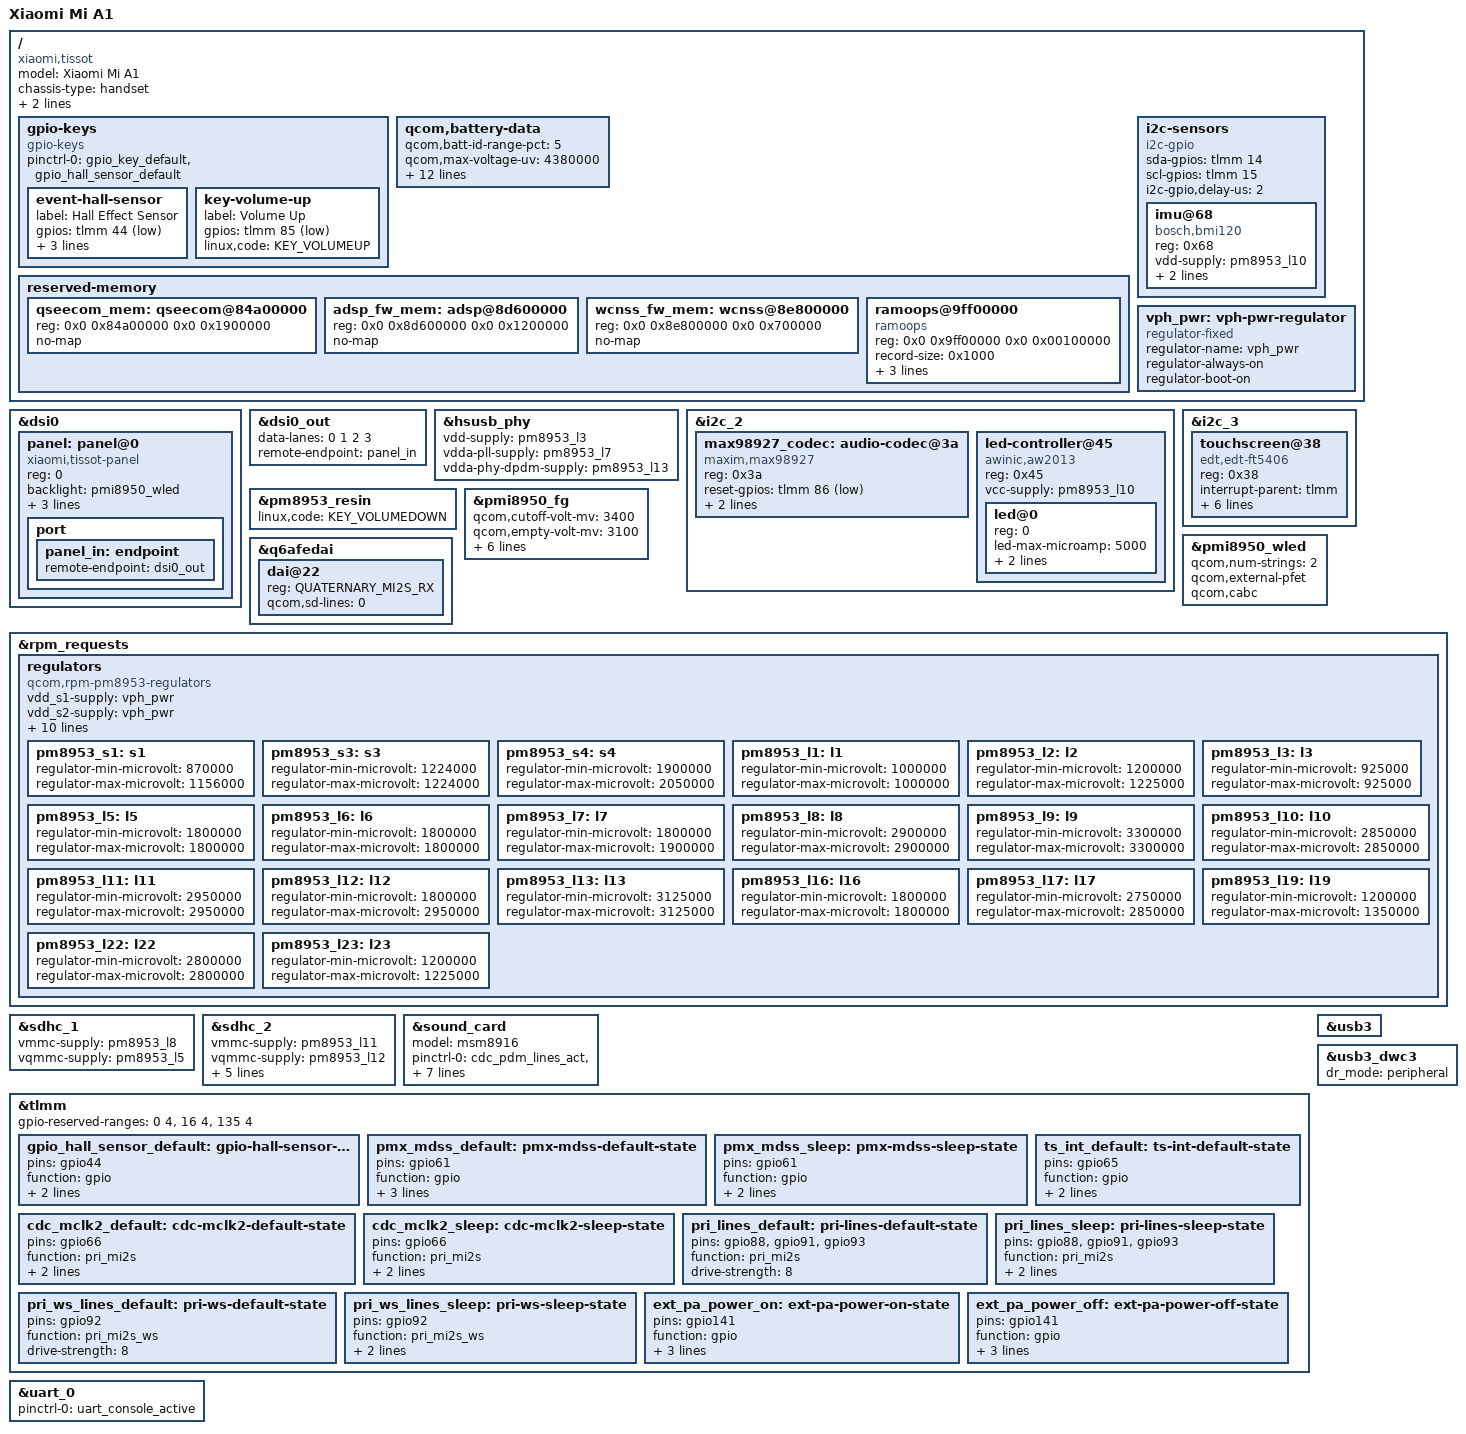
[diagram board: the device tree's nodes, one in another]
// SPDX-License-Identifier: BSD-3-Clause
/*
 * Copyright (c) 2022, Danila Tikhonov <JIaxyga@protonmail.com>
 * Copyright (c) 2022, Anton Bambura <jenneron@protonmail.com>
 */
/dts-v1/;

#include "msm8953.dtsi"
#include "pm8953.dtsi"
#include "pmi8950.dtsi"

#include <dt-bindings/gpio/gpio.h>
#include <dt-bindings/leds/common.h>

/delete-node/ &adsp_fw_mem;
/delete-node/ &qseecom_mem;
/delete-node/ &wcnss_fw_mem;

/ {
	model = "Xiaomi Mi A1";
	compatible = "xiaomi,tissot", "qcom,msm8953";
	chassis-type = "handset";
	qcom,msm-id = <293 0>;
	qcom,board-id = <0x1000b 0x00>;

	gpio-keys {
		compatible = "gpio-keys";

		pinctrl-names = "default";
		pinctrl-0 = <&gpio_key_default>, <&gpio_hall_sensor_default>;

		event-hall-sensor {
			label = "Hall Effect Sensor";
			gpios = <&tlmm 44 GPIO_ACTIVE_LOW>;
			linux,input-type = <EV_SW>;
			linux,code = <SW_LID>;
			linux,can-disable;
		};

		key-volume-up {
			label = "Volume Up";
			gpios = <&tlmm 85 GPIO_ACTIVE_LOW>;
			linux,code = <KEY_VOLUMEUP>;
		};
	};

	qcom,battery-data {
		qcom,batt-id-range-pct = <5>;
		qcom,max-voltage-uv = <4380000>;
		qcom,nom-batt-capacity-mah = <3080>;
		qcom,batt-id-kohm = <50>;
		qcom,battery-beta = <3380>;
		qcom,battery-type = "battey_qrd_coslight_3080mah";
		qcom,chg-rslow-comp-c1 = <3969816>;
		qcom,chg-rslow-comp-c2 = <7140145>;
		qcom,chg-rs-to-rslow = <997019>;
		qcom,chg-rslow-comp-thr = <0xB8>;
		qcom,checksum = <0x5DAD>;
		qcom,thermal-coefficients = [c8 86 c1 50 d3 37];
		qcom,fg-profile-data = [E2 83 DF 7C
					10 81 12 77
					65 83 51 74
					74 89 94 94
					33 82 B0 99
					A5 BC 1D C9
					55 10 02 88
					9A 7D 74 81
					8D 77 4E 83
					CD 70 15 61
					CD 7E 4F 82
					9D 99 DF BC
					B5 C9 59 0C
					24 0C 15 59
					14 70 B2 FD
					A4 3F 23 3D
					6E 33 00 00
					35 46 01 38
					FE 12 00 00
					00 00 00 00
					00 00 00 00
					97 6B B4 6A
					EF 60 0B 81
					92 6E 72 60
					3E 59 C0 79
					5B 6D 56 5B
					18 7F 64 9A
					18 E9 61 55
					5F A0 71 0C
					28 00 FF 36
					F0 11 30 03
					00 00 00 0C];
	};

	reserved-memory {
		qseecom_mem: qseecom@84a00000 {
			reg = <0x0 0x84a00000 0x0 0x1900000>;
			no-map;
		};

		adsp_fw_mem: adsp@8d600000 {
			reg = <0x0 0x8d600000 0x0 0x1200000>;
			no-map;
		};

		wcnss_fw_mem: wcnss@8e800000 {
			reg = <0x0 0x8e800000 0x0 0x700000>;
			no-map;
		};

		ramoops@9ff00000 {
			compatible = "ramoops";
			reg = <0x0 0x9ff00000 0x0 0x00100000>;
			record-size = <0x1000>;
			console-size = <0x80000>;
			ftrace-size = <0x1000>;
			pmsg-size = <0x8000>;
		};
	};

	/*
	 * We bitbang on &i2c_4 because BLSP is protected by TZ as sensors are
	 * normally proxied via ADSP firmware. GPIOs aren't protected.
	 */
	i2c-sensors {
		compatible = "i2c-gpio";
		sda-gpios = <&tlmm 14 (GPIO_ACTIVE_HIGH|GPIO_OPEN_DRAIN)>;
		scl-gpios = <&tlmm 15 (GPIO_ACTIVE_HIGH|GPIO_OPEN_DRAIN)>;
		i2c-gpio,delay-us = <2>; /* ~100 kHz */
		#address-cells = <1>;
		#size-cells = <0>;

		imu@68 {
			compatible = "bosch,bmi120";
			reg = <0x68>;

			vdd-supply = <&pm8953_l10>;
			vddio-supply = <&pm8953_l6>;
			mount-matrix = "0", "1", "0",
					"1", "0", "0",
					"0", "0", "1";
		};
	};

	vph_pwr: vph-pwr-regulator {
		compatible = "regulator-fixed";
		regulator-name = "vph_pwr";
		regulator-always-on;
		regulator-boot-on;
	};
};

&dsi0 {
	panel: panel@0 {
		compatible = "xiaomi,tissot-panel";
		reg = <0>;

		backlight = <&pmi8950_wled>;

		reset-gpios = <&tlmm 61 GPIO_ACTIVE_LOW>;

		pinctrl-names = "default", "sleep";
		pinctrl-0 = <&pmx_mdss_default &mdss_te_default>;
		pinctrl-1 = <&pmx_mdss_sleep &mdss_te_default>;

		port {
			panel_in: endpoint {
				remote-endpoint = <&dsi0_out>;
			};
		};
	};
};

&dsi0_out {
	data-lanes = <0 1 2 3>;
	remote-endpoint = <&panel_in>;
};

&hsusb_phy {
	vdd-supply = <&pm8953_l3>;
	vdda-pll-supply = <&pm8953_l7>;
	vdda-phy-dpdm-supply = <&pm8953_l13>;

	status = "okay";
};

&i2c_2 {
	status = "okay";

	max98927_codec: audio-codec@3a {
		compatible = "maxim,max98927";
		reg = <0x3a>;

		reset-gpios = <&tlmm 86 GPIO_ACTIVE_LOW>;

		vmon-slot-no = <1>;
		imon-slot-no = <1>;

		#sound-dai-cells = <1>;
	};

	led-controller@45 {
		compatible = "awinic,aw2013";
		reg = <0x45>;

		vcc-supply = <&pm8953_l10>;

		#address-cells = <1>;
		#size-cells = <0>;

		led@0 {
			reg = <0>;
			led-max-microamp = <5000>;
			function = LED_FUNCTION_INDICATOR;
			color = <LED_COLOR_ID_WHITE>;
		};
	};
};

&i2c_3 {
	status = "okay";

	touchscreen@38 {
		compatible = "edt,edt-ft5406";
		reg = <0x38>;

		interrupt-parent = <&tlmm>;
		interrupts = <65 IRQ_TYPE_EDGE_FALLING>;

		pinctrl-names = "default";
		pinctrl-0 = <&ts_int_default>;

		reset-gpios = <&tlmm 64 GPIO_ACTIVE_LOW>;

		vcc-supply = <&pm8953_l10>;

		touchscreen-size-x = <1080>;
		touchscreen-size-y = <1920>;
	};
};

&pm8953_resin {
	linux,code = <KEY_VOLUMEDOWN>;
	status = "okay";
};

&pmi8950_fg {
	qcom,cutoff-volt-mv = <3400>;
	qcom,empty-volt-mv = <3100>;
	qcom,term-current-ma = <300>;
	qcom,chg-term-current-ma = <200>;
	qcom,fg-cc-cv-thr-mv = <4370>;
	qcom,fg-vbat-estimate-diff-mv = <250>;
	qcom,bcl-lm-thr-ma = <127>;
	qcom,bcl-mh-thr-ma = <405>;
};

&pmi8950_wled {
	qcom,num-strings = <2>;
	qcom,external-pfet;
	qcom,cabc;

	status = "okay";
};

&q6afedai {
	dai@22 {
		reg = <QUATERNARY_MI2S_RX>;
		qcom,sd-lines = <0>;
	};
};

&rpm_requests {
	regulators {
		compatible = "qcom,rpm-pm8953-regulators";

		vdd_s1-supply = <&vph_pwr>;
		vdd_s2-supply = <&vph_pwr>;
		vdd_s3-supply = <&vph_pwr>;
		vdd_s4-supply = <&vph_pwr>;
		vdd_s5-supply = <&vph_pwr>;
		vdd_s6-supply = <&vph_pwr>;
		vdd_s7-supply = <&vph_pwr>;
		vdd_l1-supply = <&pm8953_s3>;
		vdd_l2_l3-supply = <&pm8953_s3>;
		vdd_l4_l5_l6_l7_l16_l19-supply = <&pm8953_s4>;
		vdd_l8_l11_l12_l13_l14_l15-supply = <&vph_pwr>;
		vdd_l9_l10_l17_l18_l22-supply = <&vph_pwr>;

		pm8953_s1: s1 {
			regulator-min-microvolt = <870000>;
			regulator-max-microvolt = <1156000>;
		};

		pm8953_s3: s3 {
			regulator-min-microvolt = <1224000>;
			regulator-max-microvolt = <1224000>;
		};

		pm8953_s4: s4 {
			regulator-min-microvolt = <1900000>;
			regulator-max-microvolt = <2050000>;
		};

		pm8953_l1: l1 {
			regulator-min-microvolt = <1000000>;
			regulator-max-microvolt = <1000000>;
		};

		pm8953_l2: l2 {
			regulator-min-microvolt = <1200000>;
			regulator-max-microvolt = <1225000>;
		};

		pm8953_l3: l3 {
			regulator-min-microvolt = <925000>;
			regulator-max-microvolt = <925000>;
		};

		pm8953_l5: l5 {
			regulator-min-microvolt = <1800000>;
			regulator-max-microvolt = <1800000>;
		};

		pm8953_l6: l6 {
			regulator-min-microvolt = <1800000>;
			regulator-max-microvolt = <1800000>;
		};

		pm8953_l7: l7 {
			regulator-min-microvolt = <1800000>;
			regulator-max-microvolt = <1900000>;
		};

		pm8953_l8: l8 {
			regulator-min-microvolt = <2900000>;
			regulator-max-microvolt = <2900000>;
		};

		pm8953_l9: l9 {
			regulator-min-microvolt = <3300000>;
			regulator-max-microvolt = <3300000>;
		};

		pm8953_l10:l10 {
			regulator-min-microvolt = <2850000>;
			regulator-max-microvolt = <2850000>;
		};

		pm8953_l11: l11 {
			regulator-min-microvolt = <2950000>;
			regulator-max-microvolt = <2950000>;
		};

		pm8953_l12: l12 {
			regulator-min-microvolt = <1800000>;
			regulator-max-microvolt = <2950000>;
		};

		pm8953_l13: l13 {
			regulator-min-microvolt = <3125000>;
			regulator-max-microvolt = <3125000>;
		};

		pm8953_l16: l16 {
			regulator-min-microvolt = <1800000>;
			regulator-max-microvolt = <1800000>;
		};

		pm8953_l17: l17 {
			regulator-min-microvolt = <2750000>;
			regulator-max-microvolt = <2850000>;
		};

		pm8953_l19: l19 {
			regulator-min-microvolt = <1200000>;
			regulator-max-microvolt = <1350000>;
		};

		pm8953_l22: l22 {
			regulator-min-microvolt = <2800000>;
			regulator-max-microvolt = <2800000>;
		};

		pm8953_l23: l23 {
			regulator-min-microvolt = <1200000>;
			regulator-max-microvolt = <1225000>;
		};
	};
};

&sdhc_1 {
	vmmc-supply = <&pm8953_l8>;
	vqmmc-supply = <&pm8953_l5>;

	status = "okay";
};

&sdhc_2 {
	vmmc-supply = <&pm8953_l11>;
	vqmmc-supply = <&pm8953_l12>;

	cd-gpios = <&tlmm 133 GPIO_ACTIVE_HIGH>;

	pinctrl-names = "default", "sleep";
	pinctrl-0 = <&sdc2_clk_on &sdc2_cmd_on &sdc2_data_on &sdc2_cd_on>;
	pinctrl-1 = <&sdc2_clk_off &sdc2_cmd_off &sdc2_data_off &sdc2_cd_off>;

	status = "okay";
};

&sound_card {
	status = "okay";

	model = "msm8916";

	pinctrl-names = "default", "sleep";
	pinctrl-0 = <&cdc_pdm_lines_act &cdc_pdm_lines_2_act &cdc_pdm_comp_lines_act &pri_lines_default &pri_ws_lines_default &ext_pa_power_on>;
	pinctrl-1 = <&cdc_pdm_lines_sus &cdc_pdm_lines_2_sus &cdc_pdm_comp_lines_sus &pri_lines_sleep &pri_ws_lines_sleep &ext_pa_power_off>;
};

&tlmm {
	gpio-reserved-ranges = <0 4>, <16 4>, <135 4>;

	gpio_hall_sensor_default: gpio-hall-sensor-state {
		pins = "gpio44";
		function = "gpio";
		drive-strength = <2>;
		bias-pull-up;
	};

	pmx_mdss_default: pmx-mdss-default-state {
		pins = "gpio61";
		function = "gpio";
		drive-strength = <8>;
		bias-disable = <0>;
		output-high;
	};

	pmx_mdss_sleep: pmx-mdss-sleep-state {
		pins = "gpio61";
		function = "gpio";
		drive-strength = <2>;
		bias-pull-down;
	};

	ts_int_default: ts-int-default-state {
		pins = "gpio65";
		function = "gpio";
		drive-strength = <2>;
		bias-pull-up;
	};

	cdc_mclk2_default: cdc-mclk2-default-state {
		pins = "gpio66";
		function = "pri_mi2s";
		drive-strength = <8>;
		bias-disable;
	};

	cdc_mclk2_sleep: cdc-mclk2-sleep-state {
		pins = "gpio66";
		function = "pri_mi2s";
		drive-strength = <2>;
		bias-pull-down;
	};

	pri_lines_default: pri-lines-default-state {
		pins = "gpio88", "gpio91", "gpio93";
		function = "pri_mi2s";
		drive-strength = <8>;
	};

	pri_lines_sleep: pri-lines-sleep-state {
		pins = "gpio88", "gpio91", "gpio93";
		function = "pri_mi2s";
		drive-strength = <2>;
		bias-pull-down;
	};

	pri_ws_lines_default: pri-ws-default-state {
		pins = "gpio92";
		function = "pri_mi2s_ws";
		drive-strength = <8>;
	};

	pri_ws_lines_sleep: pri-ws-sleep-state {
		pins = "gpio92";
		function = "pri_mi2s_ws";
		drive-strength = <2>;
		bias-pull-down;
	};

	ext_pa_power_on: ext-pa-power-on-state {
		pins = "gpio141";
		function = "gpio";
		drive-strength = <16>;
		bias-disable;
		output-high;
	};

	ext_pa_power_off: ext-pa-power-off-state {
		pins = "gpio141";
		function = "gpio";
		drive-strength = <16>;
		bias-disable;
		output-low;
	};
};

&uart_0 {
	pinctrl-names = "default";
	pinctrl-0 = <&uart_console_active>;

	status = "okay";
};

&usb3 {
	status = "okay";
};

&usb3_dwc3 {
	dr_mode = "peripheral";
};
